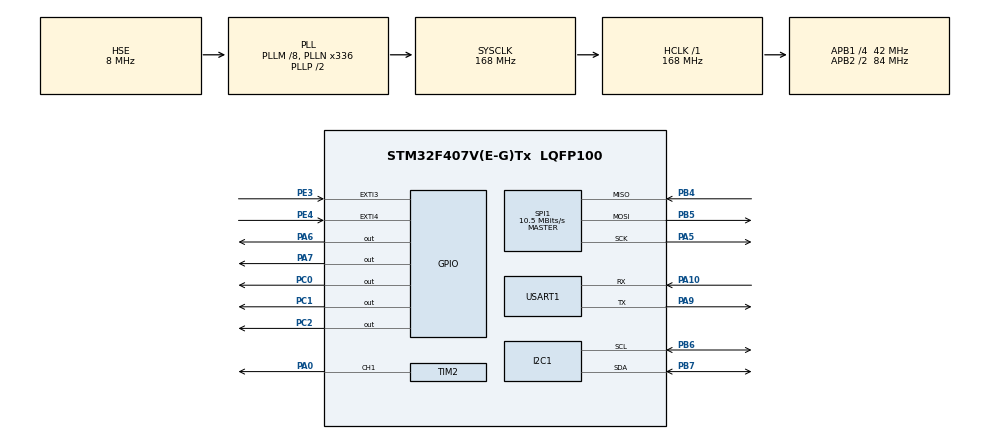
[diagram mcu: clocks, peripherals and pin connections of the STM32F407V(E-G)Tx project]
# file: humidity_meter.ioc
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Dma.I2C1_RX.0.Direction=DMA_PERIPH_TO_MEMORY
Dma.I2C1_RX.0.FIFOMode=DMA_FIFOMODE_DISABLE
Dma.I2C1_RX.0.Instance=DMA1_Stream0
Dma.I2C1_RX.0.MemDataAlignment=DMA_MDATAALIGN_BYTE
Dma.I2C1_RX.0.MemInc=DMA_MINC_ENABLE
Dma.I2C1_RX.0.Mode=DMA_NORMAL
Dma.I2C1_RX.0.PeriphDataAlignment=DMA_PDATAALIGN_BYTE
Dma.I2C1_RX.0.PeriphInc=DMA_PINC_DISABLE
Dma.I2C1_RX.0.Priority=DMA_PRIORITY_LOW
Dma.I2C1_TX.1.Direction=DMA_MEMORY_TO_PERIPH
Dma.I2C1_TX.1.FIFOMode=DMA_FIFOMODE_DISABLE
Dma.I2C1_TX.1.Instance=DMA1_Stream6
Dma.I2C1_TX.1.MemDataAlignment=DMA_MDATAALIGN_BYTE
Dma.I2C1_TX.1.MemInc=DMA_MINC_ENABLE
Dma.I2C1_TX.1.Mode=DMA_NORMAL
Dma.I2C1_TX.1.PeriphDataAlignment=DMA_PDATAALIGN_BYTE
Dma.I2C1_TX.1.PeriphInc=DMA_PINC_DISABLE
Dma.I2C1_TX.1.Priority=DMA_PRIORITY_LOW
Dma.Request0=I2C1_RX
Dma.Request1=I2C1_TX
Dma.Request2=USART1_RX
Dma.Request3=USART1_TX
Dma.Request4=SPI1_RX
Dma.Request5=SPI1_TX
Dma.SPI1_RX.4.Direction=DMA_PERIPH_TO_MEMORY
Dma.SPI1_RX.4.FIFOMode=DMA_FIFOMODE_DISABLE
Dma.SPI1_RX.4.Instance=DMA2_Stream0
Dma.SPI1_RX.4.MemDataAlignment=DMA_MDATAALIGN_BYTE
Dma.SPI1_RX.4.MemInc=DMA_MINC_ENABLE
Dma.SPI1_RX.4.Mode=DMA_NORMAL
Dma.SPI1_RX.4.PeriphDataAlignment=DMA_PDATAALIGN_BYTE
Dma.SPI1_RX.4.PeriphInc=DMA_PINC_DISABLE
Dma.SPI1_RX.4.Priority=DMA_PRIORITY_LOW
Dma.SPI1_TX.5.Direction=DMA_MEMORY_TO_PERIPH
Dma.SPI1_TX.5.FIFOMode=DMA_FIFOMODE_DISABLE
Dma.SPI1_TX.5.Instance=DMA2_Stream3
Dma.SPI1_TX.5.MemDataAlignment=DMA_MDATAALIGN_BYTE
Dma.SPI1_TX.5.MemInc=DMA_MINC_ENABLE
Dma.SPI1_TX.5.Mode=DMA_NORMAL
Dma.SPI1_TX.5.PeriphDataAlignment=DMA_PDATAALIGN_BYTE
Dma.SPI1_TX.5.PeriphInc=DMA_PINC_DISABLE
Dma.SPI1_TX.5.Priority=DMA_PRIORITY_LOW
Dma.USART1_RX.2.Direction=DMA_PERIPH_TO_MEMORY
Dma.USART1_RX.2.FIFOMode=DMA_FIFOMODE_DISABLE
Dma.USART1_RX.2.Instance=DMA2_Stream2
Dma.USART1_RX.2.MemDataAlignment=DMA_MDATAALIGN_BYTE
Dma.USART1_RX.2.MemInc=DMA_MINC_ENABLE
Dma.USART1_RX.2.Mode=DMA_NORMAL
Dma.USART1_RX.2.PeriphDataAlignment=DMA_PDATAALIGN_BYTE
Dma.USART1_RX.2.PeriphInc=DMA_PINC_DISABLE
Dma.USART1_RX.2.Priority=DMA_PRIORITY_LOW
Dma.USART1_TX.3.Direction=DMA_MEMORY_TO_PERIPH
Dma.USART1_TX.3.FIFOMode=DMA_FIFOMODE_DISABLE
Dma.USART1_TX.3.Instance=DMA2_Stream7
Dma.USART1_TX.3.MemDataAlignment=DMA_MDATAALIGN_BYTE
Dma.USART1_TX.3.MemInc=DMA_MINC_ENABLE
Dma.USART1_TX.3.Mode=DMA_NORMAL
Dma.USART1_TX.3.PeriphDataAlignment=DMA_PDATAALIGN_BYTE
Dma.USART1_TX.3.PeriphInc=DMA_PINC_DISABLE
Dma.USART1_TX.3.Priority=DMA_PRIORITY_LOW
FREERTOS.Tasks01=defaultTask,24,128,StartDefaultTask,Default,NULL,Dynamic,NULL,NULL
Mcu.Family=STM32F4
Mcu.Name=STM32F407V(E-G)Tx
Mcu.Package=LQFP100
NVIC.DMA1_Stream0_IRQn=true\:5\:0\:false\:false\:true\:true\:false\:true\:true
NVIC.DMA1_Stream6_IRQn=true\:5\:0\:false\:false\:true\:true\:false\:true\:true
NVIC.DMA2_Stream0_IRQn=true\:5\:0\:false\:false\:true\:true\:false\:true\:true
NVIC.DMA2_Stream2_IRQn=true\:5\:0\:false\:false\:true\:true\:false\:true\:true
NVIC.DMA2_Stream3_IRQn=true\:5\:0\:false\:false\:true\:true\:false\:true\:true
NVIC.DMA2_Stream7_IRQn=true\:5\:0\:false\:false\:true\:true\:false\:true\:true
NVIC.EXTI3_IRQn=true\:5\:0\:false\:false\:true\:true\:true\:true\:true
NVIC.EXTI4_IRQn=true\:5\:0\:false\:false\:true\:true\:true\:true\:true
NVIC.I2C1_ER_IRQn=true\:5\:0\:false\:false\:true\:true\:true\:true\:true
NVIC.I2C1_EV_IRQn=true\:5\:0\:false\:false\:true\:true\:true\:true\:true
NVIC.PriorityGroup=NVIC_PRIORITYGROUP_4
NVIC.SPI1_IRQn=true\:5\:0\:false\:false\:true\:true\:true\:true\:true
NVIC.TIM6_DAC_IRQn=true\:5\:0\:false\:false\:true\:true\:true\:true\:true
NVIC.TIM7_IRQn=true\:15\:0\:false\:false\:true\:false\:false\:true\:true
NVIC.TimeBase=TIM7_IRQn
NVIC.TimeBaseIP=TIM7
NVIC.USART1_IRQn=true\:5\:0\:false\:false\:true\:true\:true\:true\:true
PA0-WKUP.Signal=S_TIM2_CH1_ETR
PA10.Mode=Asynchronous
PA10.Signal=USART1_RX
PA13.Mode=Serial_Wire
PA13.Signal=SYS_JTMS-SWDIO
PA14.Mode=Serial_Wire
PA14.Signal=SYS_JTCK-SWCLK
PA5.Mode=Full_Duplex_Master
PA5.Signal=SPI1_SCK
PA6.GPIO_PuPd=GPIO_NOPULL
PA6.Signal=GPIO_Output
PA7.GPIO_PuPd=GPIO_NOPULL
PA7.Signal=GPIO_Output
PA9.Mode=Asynchronous
PA9.Signal=USART1_TX
PB4.Mode=Full_Duplex_Master
PB4.Signal=SPI1_MISO
PB5.Mode=Full_Duplex_Master
PB5.Signal=SPI1_MOSI
PB6.Mode=I2C
PB6.Signal=I2C1_SCL
PB7.Mode=I2C
PB7.Signal=I2C1_SDA
PC0.GPIO_ModeDefaultOutputPP=GPIO_MODE_OUTPUT_PP
PC0.GPIO_PuPd=GPIO_NOPULL
PC0.Signal=GPIO_Output
PC1.GPIO_ModeDefaultOutputPP=GPIO_MODE_OUTPUT_PP
PC1.GPIO_PuPd=GPIO_NOPULL
PC1.Signal=GPIO_Output
PC2.GPIO_ModeDefaultOutputPP=GPIO_MODE_OUTPUT_PP
PC2.GPIO_PuPd=GPIO_NOPULL
PC2.Signal=GPIO_Output
PE3.GPIO_ModeDefaultEXTI=GPIO_MODE_IT_FALLING
PE3.GPIO_PuPd=GPIO_PULLUP
PE3.Signal=GPXTI3
PE4.GPIO_ModeDefaultEXTI=GPIO_MODE_IT_FALLING
PE4.GPIO_PuPd=GPIO_PULLUP
PE4.Signal=GPXTI4
PH0-OSC_IN.Mode=HSE-External-Oscillator
PH0-OSC_IN.Signal=RCC_OSC_IN
PH1-OSC_OUT.Mode=HSE-External-Oscillator
PH1-OSC_OUT.Signal=RCC_OSC_OUT
ProjectManager.HeapSize=0x200
ProjectManager.StackSize=0x400
ProjectManager.TargetToolchain=CMake
RCC.48MHZClocksFreq_Value=84000000
RCC.AHBFreq_Value=168000000
RCC.APB1CLKDivider=RCC_HCLK_DIV4
RCC.APB1Freq_Value=42000000
RCC.APB1TimFreq_Value=84000000
RCC.APB2CLKDivider=RCC_HCLK_DIV2
RCC.APB2Freq_Value=84000000
RCC.APB2TimFreq_Value=168000000
RCC.CortexFreq_Value=168000000
RCC.HCLKFreq_Value=168000000
RCC.HSE_VALUE=8000000
RCC.HSI_VALUE=16000000
RCC.LSE_VALUE=32768
RCC.PLLM=8
RCC.PLLN=336
RCC.PLLSourceVirtual=RCC_PLLSOURCE_HSE
RCC.SYSCLKFreq_VALUE=168000000
RCC.SYSCLKSource=RCC_SYSCLKSOURCE_PLLCLK
RCC.VCOOutputFreq_Value=336000000
SH.S_TIM2_CH1_ETR.0=TIM2_CH1,PWM Generation1 CH1
SPI1.BaudRatePrescaler=SPI_BAUDRATEPRESCALER_8
SPI1.CalculateBaudRate=10.5 MBits/s
SPI1.Direction=SPI_DIRECTION_2LINES
SPI1.Mode=SPI_MODE_MASTER
SPI1.VirtualType=VM_MASTER
TIM2.AutoReloadPreload=TIM_AUTORELOAD_PRELOAD_DISABLE
TIM2.Channel-PWM\ Generation1\ CH1=TIM_CHANNEL_1
TIM2.Period=100
TIM2.Prescaler=84-1
TIM2.Pulse-PWM\ Generation1\ CH1=100
TIM6.Period=10000-1
TIM6.Prescaler=8400-1
USART1.VirtualMode=VM_ASYNC
VP_FREERTOS_VS_CMSIS_V2.Mode=CMSIS_V2
VP_SYS_VS_tim7.Mode=TIM7
VP_TIM2_VS_ClockSourceINT.Mode=Internal
VP_TIM6_VS_ClockSourceINT.Mode=Enable_Timer
board=custom

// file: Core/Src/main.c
/* USER CODE BEGIN Header */
/* USER CODE END Header */
#include "main.h"
#include "cmsis_os.h"
#include "dma.h"
#include "gpio.h"
#include "i2c.h"
#include "spi.h"
#include "tim.h"
#include "usart.h"

/* USER CODE BEGIN Includes */
#include "board_config.h"
#include "system_state.h"
#include "task_config.h"
#include "led_blinking_task.h"
#include "sensor_measure_task.h"

/* USER CODE END Includes */

void SystemClock_Config(void);
void MX_FREERTOS_Init(void);

int main(void) {

    /* MCU Configuration--------------------------------------------------------*/

    /* Reset of all peripherals, Initializes the Flash interface and the Systick.
     */
    HAL_Init();

    /* Configure the system clock */
    SystemClock_Config();

    /* Initialize all configured peripherals */
    MX_GPIO_Init();
    MX_DMA_Init();
    MX_I2C1_Init();
    MX_SPI1_Init();
    MX_USART1_UART_Init();
    MX_TIM6_Init();
    MX_TIM2_Init();
    /* USER CODE BEGIN 2 */
    // --------------------------------------------------------------------------
    // Initial System State and Create TASK
    // 1.1 Initial System State
    // --------------------------------------------------------------------------
    system_state_init();
    tasks_create();

    // --------------------------------------------------------------------------
    // 1. osKernelInitialize: Initializes the Ready, Blocked, Suspended lists of
    // FreeRTOS.
    // 2. MX_FREERTOS_Init:  Created CubeMX Tasks. If using native API ,this is
    // only has a defaultTask.
    // 3. osKernelStart: Sets up SysTick(OS Tick Timer), Creates Idle Tasks,
    // Starts the first Task
    // --------------------------------------------------------------------------
    /* USER CODE END 2 */

    /* Init scheduler */
    osKernelInitialize(); /* Call init function for freertos objects (in
                             cmsis_os2.c) */
    MX_FREERTOS_Init();

    /* Start scheduler */
    osKernelStart();

    /* We should never get here as control is now taken by the scheduler */

    /* Infinite loop */

}

void SystemClock_Config(void) {
    RCC_OscInitTypeDef RCC_OscInitStruct = {0};
    RCC_ClkInitTypeDef RCC_ClkInitStruct = {0};

    /** Configure the main internal regulator output voltage
     */
    __HAL_RCC_PWR_CLK_ENABLE();
    __HAL_PWR_VOLTAGESCALING_CONFIG(PWR_REGULATOR_VOLTAGE_SCALE1);

    /** Initializes the RCC Oscillators according to the specified parameters
     * in the RCC_OscInitTypeDef structure.
     */
    RCC_OscInitStruct.OscillatorType = RCC_OSCILLATORTYPE_HSE;
    RCC_OscInitStruct.HSEState = RCC_HSE_ON;
    RCC_OscInitStruct.PLL.PLLState = RCC_PLL_ON;
    RCC_OscInitStruct.PLL.PLLSource = RCC_PLLSOURCE_HSE;
    RCC_OscInitStruct.PLL.PLLM = 8;
    RCC_OscInitStruct.PLL.PLLN = 336;
    RCC_OscInitStruct.PLL.PLLP = RCC_PLLP_DIV2;
    RCC_OscInitStruct.PLL.PLLQ = 4;
    if (HAL_RCC_OscConfig(&RCC_OscInitStruct) != HAL_OK) {
        Error_Handler();
    }

    /** Initializes the CPU, AHB and APB buses clocks
     */
    RCC_ClkInitStruct.ClockType = RCC_CLOCKTYPE_HCLK | RCC_CLOCKTYPE_SYSCLK | RCC_CLOCKTYPE_PCLK1 | RCC_CLOCKTYPE_PCLK2;
    RCC_ClkInitStruct.SYSCLKSource = RCC_SYSCLKSOURCE_PLLCLK;
    RCC_ClkInitStruct.AHBCLKDivider = RCC_SYSCLK_DIV1;
    RCC_ClkInitStruct.APB1CLKDivider = RCC_HCLK_DIV4;
    RCC_ClkInitStruct.APB2CLKDivider = RCC_HCLK_DIV2;

    if (HAL_RCC_ClockConfig(&RCC_ClkInitStruct, FLASH_LATENCY_5) != HAL_OK) {
        Error_Handler();
    }
}

void Error_Handler(void) {
}

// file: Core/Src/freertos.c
/* USER CODE BEGIN Header */
/**
 ******************************************************************************
 * File Name          : freertos.c
 * Description        : Code for freertos applications
 ******************************************************************************
 * @attention
 *
 * Copyright (c) 2026 STMicroelectronics.
 * All rights reserved.
 *
 * This software is licensed under terms that can be found in the LICENSE file
 * in the root directory of this software component.
 * If no LICENSE file comes with this software, it is provided AS-IS.
 *
 ******************************************************************************
 */
/* USER CODE END Header */

#include "FreeRTOS.h"
#include "cmsis_os.h"
#include "main.h"
#include "task.h"

/* Definitions for defaultTask */
osThreadId_t defaultTaskHandle;
const osThreadAttr_t defaultTask_attributes = {
    .name = "defaultTask",
    .stack_size = 128 * 4,
    .priority = (osPriority_t)osPriorityNormal,
};

void StartDefaultTask(void *argument);

void MX_FREERTOS_Init(void); /* (MISRA C 2004 rule 8.1) */

void MX_FREERTOS_Init(void) {

  /* Create the thread(s) */
  /* creation of defaultTask */
  defaultTaskHandle =
      osThreadNew(StartDefaultTask, NULL, &defaultTask_attributes);

}

void StartDefaultTask(void *argument) {
  /* USER CODE BEGIN StartDefaultTask */
  /* Infinite loop */
  vTaskDelete(NULL);
  for (;;) {
    osDelay(1);
  }
  vTaskDelete(NULL);
  /* USER CODE END StartDefaultTask */
}
